# LPC111x_LPC11Cxx register map
File version: 6
LPC11xx, LPC11Cxx, LPC11xxL, LPC11xxXL
CPU: CM0 r0p0, little endian, no MPU, no FPU, 0x2 interrupt priority bits, 0x0 interrupts
Registers are 32-bit, read-write, reset 0x0 unless marked. A register's access mark holds for its fields unless they carry their own. Offsets are from the block's base; lines under a group give offsets from that group; [hi:lo] are bit positions; {n}, {i} and the like mark numbered series; 'fields as' and 'values as' point back to an identical list; <NAME> marks a mode.

## Memory map
0x40000000 I2C size 0xFFF
0x40004000 WWDT size 0xFFF — Product name title=UM10398 Chapter title=LPC111x/LPC11Cxx Windowed WatchDog Timer (WDT) Modification date=9/19/2011 Major revision=6 Minor revision=not available
0x40008000 UART size 0xFFF — Product name title=UM10398 Chapter title=LPC111x/LPC11Cxx UART Modification date=9/19/2011 Major revision=7 Minor revision=not available
0x4000C000 CT16B0 size 0xFFF — Product name title=UM10398 Chapter title=LPC1100XL series: 16-bit counter/timer CT16B0/1 Modification date=2/22/2012 Major revision=8 Minor revision=not available
0x40010000 CT16B1 size 0xFFF — Product name title=UM10398 Chapter title=LPC1100XL series: 16-bit counter/timer CT16B0/1 Modification date=2/22/2012 Major revision=8 Minor revision=not available
0x40014000 CT32B0 size 0xFFF — Product name title=UM10398 Chapter title=LPC1100XL series: 32-bit counter/timer CT32B0/1 Modification date=2/22/2012 Major revision=8 Minor revision=not available
0x40018000 CT32B1 size 0xFFF — Product name title=UM10398 Chapter title=LPC1100XL series: 32-bit counter/timer CT32B0/1 Modification date=2/22/2012 Major revision=8 Minor revision=not available
0x4001C000 ADC size 0xFFF — 10-bit ADC
0x40038000 PMU size 0xFFF — power management unit
0x4003C000 FLASHCTRL size 0xFFF — Product name title=UM10462 Chapter title=LPC11U1x Flash programming firmware Modification date=3/17/2011 Major revision=0 Minor revision=3
0x40040000 SPI0 size 0xFFF
0x40044000 IOCON size 0xFFF — Product name title=UM10398 Chapter title=LPC1100XL series: I/O configuration (IOCONFIG) Modification date=2/22/2012 Major revision=8 Minor revision=not available
0x40048000 SYSCON size 0xFFF — Product name title=UM10398 Chapter title=LPC111x/LPC11Cxx System configuration (SYSCON) Modification date=2/22/2012 Major revision=8 Minor revision=not available
0x40050000 C_CAN size 0xFFF — Product name title=UM10398 Chapter title=LPC111x/LPC11Cxx C_CAN controller Modification date=9/19/2011 Major revision=7 Minor revision=not available
0x40058000 SPI1 size 0xFFF — SPI0
0x50000000 GPIO0 size 0xFFFFFF
0x50010000 GPIO1 size 0xFFFFFF — GPIO0
0x50020000 GPIO2 size 0xFFFFFF — GPIO0
0x50030000 GPIO3 size 0xFFFFFF — GPIO0

## Interrupts
{n} PIO0_{n} (SYSCON) (n=0..11)
12 PIO1_0 (SYSCON)
13 C_CAN
14 SPI1
15 I2C
16 CT16B0
17 CT16B1
18 CT32B0
19 CT32B1
20 SPI0
21 UART
24 ADC
25 WDT (WWDT)
26 BOD (SYSCON)
27 FMC (FLASHCTRL)
28 GPIO3
29 GPIO2
30 GPIO1
31 GPIO0

## WWDT — Product name title=UM10398 Chapter title=LPC111x/LPC11Cxx Windowed WatchDog Timer (WDT) Modification date=9/19/2011 Major revision=6 Minor revision=not available
Base 0x40004000
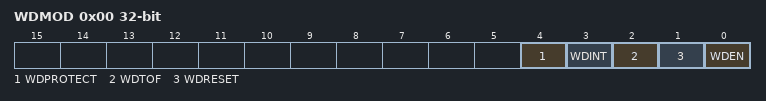
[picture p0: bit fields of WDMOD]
0x00 WDMOD — Watchdog mode register. This register contains the basic mode and status of the Watchdog Timer.
  [4] WDPROTECT — Watchdog update mode. This bit is Set Only.
    0=ANYTIME (The watchdog reload value (WDTC) can be changed at any time.); 1=LOWCOUNTER (The watchdog reload value (WDTC) can be changed only after the counter is below the value of WDWARNINT and WDWINDOW. Note: this mode is intended for use only when WDRESET =1.)
  [3] WDINT — Watchdog interrupt flag. Set when the timer reaches the value in WDWARNINT. Cleared by software.
  [2] WDTOF — Watchdog time-out flag. Set when the watchdog timer times out, by a feed error, or by events associated with WDPROTECT, cleared by software. Causes a chip reset if WDRESET = 1.
  [1] WDRESET — Watchdog reset enable bit. This bit is Set Only.
    0=NORESET (A watchdog timeout will not cause a chip reset.); 1=RESET (A watchdog timeout will cause a chip reset.)
  [0] WDEN — Watchdog enable bit. This bit is Set Only. Setting this bit to one also locks the watchdog clock source. Once the watchdog timer is enabled, the watchdog timer clock source cannot be changed. If the watchdog timer is needed in Deep-sleep mode, the watchdog clock source must be changed to the watchdog oscillator before setting this bit to one.
    0=STOPPED (The watchdog timer is stopped.); 1=RUN (The watchdog timer is running.)
0x04 WDTC reset 0xFF — Watchdog timer constant register. This register determines the time-out value.
  [23:0] Count — Watchdog time-out interval.
0x08 WDFEED wo reset not defined — Watchdog feed sequence register. Writing 0xAA followed by 0x55 to this register reloads the Watchdog timer with the value contained in WDTC.
  [7:0] Feed — Feed value should be 0xAA followed by 0x55.
0x0C WDTV ro reset 0xFF — Watchdog timer value register. This register reads out the current value of the Watchdog timer.
  [23:0] Count — Counter timer value.
0x14 WDWARNINT — Watchdog Warning Interrupt compare value.
  [9:0] WARNINT — Watchdog warning interrupt compare value.
0x18 WDWINDOW reset 0xFFFFFF — Watchdog Window compare value.
  [23:0] WINDOW — Watchdog window value.
